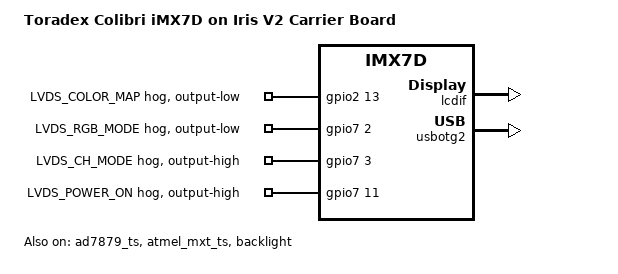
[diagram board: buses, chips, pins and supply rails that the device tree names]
/dts-v1/;
#include "imx7d-colibri.dtsi"
#include "imx7-colibri-iris-v2.dtsi"
/ {
	model = "Toradex Colibri iMX7D on Iris V2 Carrier Board";
	compatible = "toradex,colibri-imx7d-iris-v2",
		     "toradex,colibri-imx7d",
		     "fsl,imx7d";
};
&ad7879_ts {
	status = "okay";
};
&atmel_mxt_ts {
	status = "okay";
};
&backlight {
	status = "okay";
};
&gpio2 {
	lvds-color-map-hog {
		gpio-hog;
		gpios = <13 GPIO_ACTIVE_HIGH>;  
		line-name = "LVDS_COLOR_MAP";
		output-low;
	};
};
&gpio7 {
	lvds-rgb-mode-hog {
		gpio-hog;
		gpios = <2 GPIO_ACTIVE_HIGH>;  
		line-name = "LVDS_RGB_MODE";
		output-low;
	};
	lvds-ch-mode-hog {
		gpio-hog;
		gpios = <3 GPIO_ACTIVE_HIGH>;  
		line-name = "LVDS_CH_MODE";
		output-high;
	};
	lvds-power-on-hog {
		gpio-hog;
		gpios = <11 GPIO_ACTIVE_HIGH>;  
		line-name = "LVDS_POWER_ON";
		output-high;
	};
};
&lcdif {
	status = "okay";
};
&panel_dpi {
	status = "okay";
};
&usbotg2 {
	disable-over-current;
	status = "okay";
};
